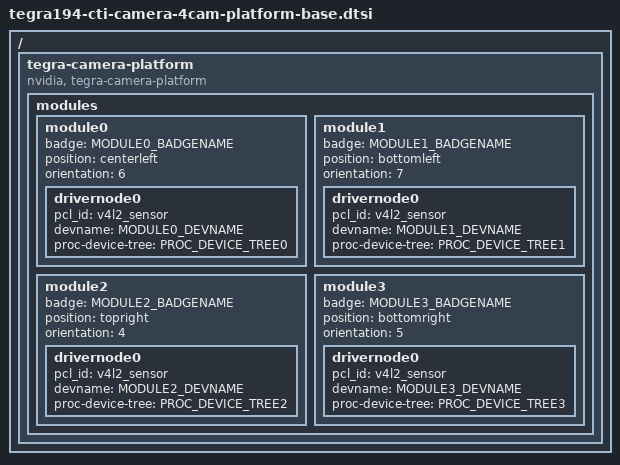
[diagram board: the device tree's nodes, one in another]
/ {

	tegra-camera-platform {
		compatible = "nvidia, tegra-camera-platform";
		status = "okay";
		modules {
			module0 {
				badge = MODULE0_BADGENAME;
				position = "centerleft";
				orientation = "6";
				status = "okay";
				drivernode0 {
					/* Declare PCL support driver (classically known as guid)  */
					pcl_id = "v4l2_sensor";
					/* Driver v4l2 device name */
					devname = MODULE0_DEVNAME;
					/* Declare the device-tree hierarchy to driver instance */
					proc-device-tree = PROC_DEVICE_TREE0;
					status = "okay";
				};
			};
			module1 {
				badge = MODULE1_BADGENAME;
				position = "bottomleft";
				orientation = "7";
				status = "okay";
				drivernode0 {
					/* Declare PCL support driver (classically known as guid)  */
					pcl_id = "v4l2_sensor";
					/* Driver v4l2 device name */
					devname = MODULE1_DEVNAME;
					/* Declare the device-tree hierarchy to driver instance */
					proc-device-tree = PROC_DEVICE_TREE1;
					status = "okay";
				};
			};
			module2 {
				badge = MODULE2_BADGENAME;
				position = "topright";
				orientation = "4";
				status = "okay";
				drivernode0 {
					/* Declare PCL support driver (classically known as guid)  */
					pcl_id = "v4l2_sensor";
					/* Driver v4l2 device name */
					devname = MODULE2_DEVNAME;
					/* Declare the device-tree hierarchy to driver instance */
					proc-device-tree = PROC_DEVICE_TREE2;
					status = "okay";
				};
			};
			module3 {
				badge = MODULE3_BADGENAME;
				position = "bottomright";
				orientation = "5";
				status = "okay";
				drivernode0 {
					/* Declare PCL support driver (classically known as guid)  */
					pcl_id = "v4l2_sensor";
					/* Driver v4l2 device name */
					devname = MODULE3_DEVNAME;
					/* Declare the device-tree hierarchy to driver instance */
					proc-device-tree = PROC_DEVICE_TREE3;
					status = "okay";
				};
			};
		};
	};
};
